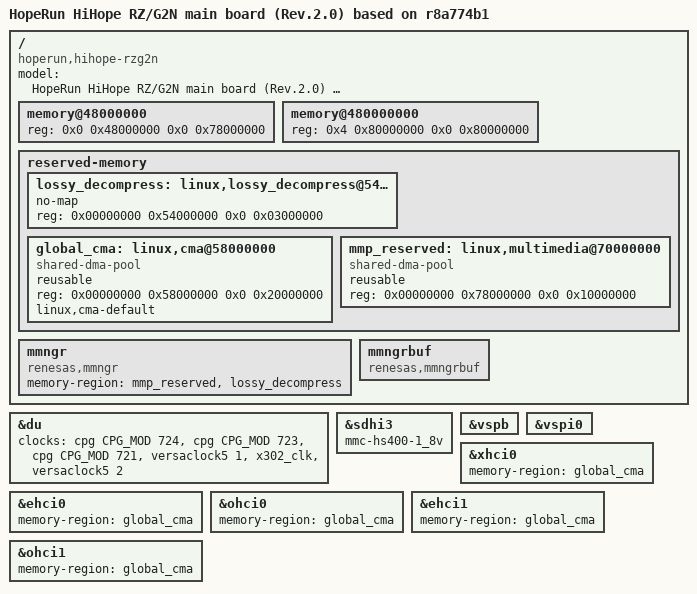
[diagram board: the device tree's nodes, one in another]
// SPDX-License-Identifier: GPL-2.0
/*
 * Device Tree Source for the HiHope RZ/G2N Rev.2.0 main board
 *
 * Copyright (C) 2019 Renesas Electronics Corp.
 */

/dts-v1/;
#include "r8a774b1.dtsi"
#include "hihope-rev2.dtsi"

/ {
	model = "HopeRun HiHope RZ/G2N main board (Rev.2.0) based on r8a774b1";
	compatible = "hoperun,hihope-rzg2n", "renesas,r8a774b1";

	memory@48000000 {
		device_type = "memory";
		/* first 128MB is reserved for secure area. */
		reg = <0x0 0x48000000 0x0 0x78000000>;
	};

	memory@480000000 {
		device_type = "memory";
		reg = <0x4 0x80000000 0x0 0x80000000>;
	};

	reserved-memory {
		#address-cells = <2>;
		#size-cells = <2>;
		ranges;

		/* device specific region for Lossy Decompression */
		lossy_decompress: linux,lossy_decompress@54000000 {
			no-map;
			reg = <0x00000000 0x54000000 0x0 0x03000000>;
		};

		/* global autoconfigured region for contiguous allocations */
		global_cma: linux,cma@58000000 {
			compatible = "shared-dma-pool";
			reusable;
			reg = <0x00000000 0x58000000 0x0 0x20000000>;
			linux,cma-default;
		};

		/* device specific region for contiguous allocations */
		mmp_reserved: linux,multimedia@70000000 {
			compatible = "shared-dma-pool";
			reusable;
			reg = <0x00000000 0x78000000 0x0 0x10000000>;
		};
	};

	mmngr {
		compatible = "renesas,mmngr";
		memory-region = <&mmp_reserved>, <&lossy_decompress>;
	};

	mmngrbuf {
		compatible = "renesas,mmngrbuf";
	};
};

&du {
	clocks = <&cpg CPG_MOD 724>,
		 <&cpg CPG_MOD 723>,
		 <&cpg CPG_MOD 721>,
		 <&versaclock5 1>,
		 <&x302_clk>,
		 <&versaclock5 2>;
	clock-names = "du.0", "du.1", "du.3",
		      "dclkin.0", "dclkin.1", "dclkin.3";
};

&sdhi3 {
	mmc-hs400-1_8v;
};

&vspb {
	status = "okay";
};

&vspi0 {
	status = "okay";
};

&xhci0 {
	memory-region = <&global_cma>;
};

&ehci0 {
	memory-region = <&global_cma>;
};

&ohci0 {
	memory-region = <&global_cma>;
};

&ehci1 {
	memory-region = <&global_cma>;
};

&ohci1 {
	memory-region = <&global_cma>;
};
